# MAILBOX13 register map
Vendor: Texas Instruments
Peripheral module from a debugger description file (folder am571x).
Registers are 32-bit, read-only, reset 0x0 unless marked. A register's access mark holds for its fields unless they carry their own. Offsets are as the file gives them; lines under a group give offsets from that group; [hi:lo] are bit positions; {n}, {i} and the like mark numbered series; 'fields as' and 'values as' point back to an identical list; <NAME> marks a mode.

## MAILBOX13
0x00 MAILBOX_REVISION reset not defined — This register contains the IP revision code
  [31:0] REVISION — IP Revision
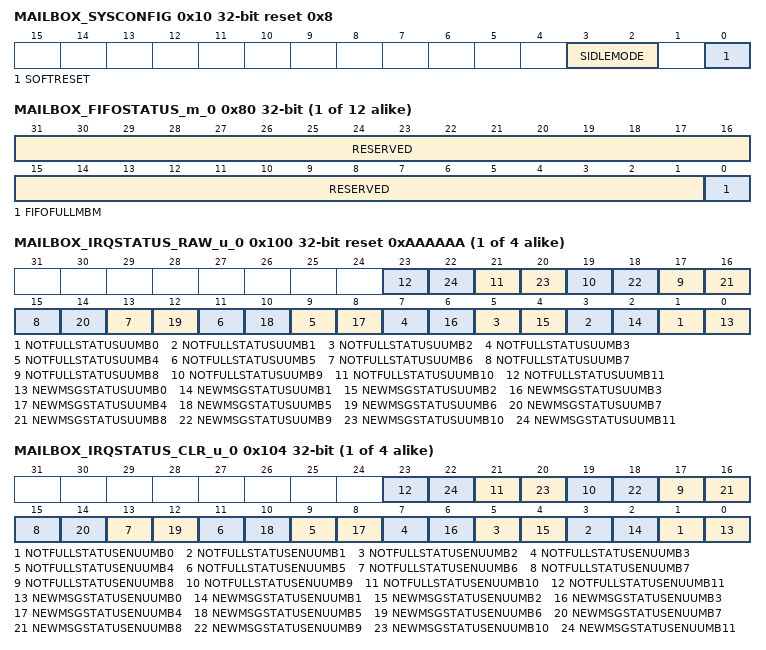
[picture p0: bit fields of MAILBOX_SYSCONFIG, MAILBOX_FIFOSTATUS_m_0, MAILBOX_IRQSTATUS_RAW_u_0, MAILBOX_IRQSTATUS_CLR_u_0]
0x10 MAILBOX_SYSCONFIG rw reset 0x8 — This register controls the various parameters of the communication interface
  [3:2] SIDLEMODE — Idle Mode
    0=b00 (Force-idle. An idle request is acknowledged unconditionally); 1=b01 (No-idle. An idle request is never acknowledged); 2=b10 (Smart-idle. Acknowledgement to an idle request is given based on the internal activity of the module based on the internal activity of the module); 3=b11 (reserved do not use)
  [0] SOFTRESET
    0=b0 (Soft/Hard reset done); 0=b0 (No action); 1=b1 (Reset is ongoing); 1=b1 (Start the soft reset sequence)
{0x40+4i} MAILBOX_MESSAGE_m_{i} rw (i=0..11) — The message register stores the next to be read message of the mailbox. Reads remove the message from the FIFO queue.
  [31:0] MESSAGEVALUEMBM — Message in Mailbox
{0x80+4i} MAILBOX_FIFOSTATUS_m_{i} (i=0..11) — The FIFO status register has the status related to the mailbox internal FIFO
  [31:1] RESERVED — Reads returns 0
  [0] FIFOFULLMBM — Full flag for Mailbox
    0=Mailbox_FIFO_is_not_full; 1=Mailbox_FIFO_is_full
{0xC0+4i} MAILBOX_MSGSTATUS_m_{i} (i=0..11) — The message status register has the status of the messages in the mailbox.
  [2:0] NBOFMSGMBM — Number of unread messages in Mailbox Note: Limited to four messages per mailbox.
{0x100+0x10*i} MAILBOX_IRQSTATUS_RAW_u_{i} access per field reset 0xAAAAAA (i=0..3) — The interrupt status register has the raw status for each event that may be responsible for the generation of an interrupt to the corresponding user - write 1 to a given bit sets this bit. This register is mainly used for debug purpose.
  [2n+1] NOTFULLSTATUSUUMB{n} rw (n=0..11) — NotFull Status bit for User u, Mailbox {n}
    0=No_event_pending_(message_queue_full); 0=No_action; 1=Event_pending_(message_queue_not_full); 1=Set_the_event_(for_debug)
  [2n] NEWMSGSTATUSUUMB{n} rw (n=0..11) — NewMessage Status bit for User u, Mailbox {n}
    0=No_event_(message)_pending; 0=No_action; 1=Event_(message)_pending; 1=Set_the_event_(for_debug)
{0x104+0x10*i} MAILBOX_IRQSTATUS_CLR_u_{i} access per field (i=0..3) — The interrupt status register has the status combined with irq-enable for each event that may be responsible for the generation of an interrupt to the corresponding user - write 1 to a given bit resets this bit
  [2n+1] NOTFULLSTATUSENUUMB{n} rw (n=0..11) — NotFull Status bit for User u, Mailbox {n}
    0=No_event_pending_(message_queue_full); 0=No_action; 1=Event_pending_(message_queue_not_full); 1=Clear_pending_event,_if_any
  [2n] NEWMSGSTATUSENUUMB{n} rw (n=0..11) — NewMessage Status bit for User u, Mailbox {n}
    0=No_event_(message)_pending; 0=No_action; 1=Event_(message)_pending; 1=Clear_pending_event,_if_any
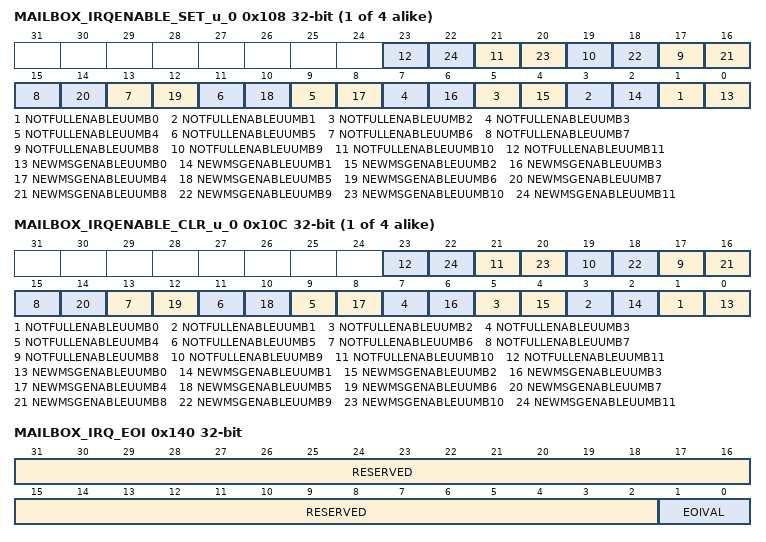
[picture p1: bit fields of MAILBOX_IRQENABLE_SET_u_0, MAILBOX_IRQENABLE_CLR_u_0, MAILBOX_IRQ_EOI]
{0x108+0x10*i} MAILBOX_IRQENABLE_SET_u_{i} access per field (i=0..3) — The interrupt enable register enables to unmask the module internal source of interrupt to the corresponding user. This register is write 1 to set.
  [all] fields
    0=Interupt_disabled; 0=No_action; 1=Interrupt_enabled; 1=Enable_interrupt
  [2n+1] NOTFULLENABLEUUMB{n} rw (n=0..11) — NotFull Enable bit for User u, Mailbox {n}
  [2n] NEWMSGENABLEUUMB{n} rw (n=0..11) — NewMessage Enable bit for User u, Mailbox {n}
{0x10C+0x10*i} MAILBOX_IRQENABLE_CLR_u_{i} access per field (i=0..3) — The interrupt enable register enables to mask the module internal source of interrupt to the corresponding user. This register is write 1 to clear.
  [all] fields
    0=Interupt_disabled; 0=No_action; 1=Interrupt_enabled; 1=Disable_interrupt
  [2n+1] NOTFULLENABLEUUMB{n} rw (n=0..11) — NotFull Enable bit for User u, Mailbox {n}
  [2n] NEWMSGENABLEUUMB{n} rw (n=0..11) — NewMessage Enable bit for User u, Mailbox {n}
0x140 MAILBOX_IRQ_EOI wo — This register is used for the software EOI clearance of the pulse. This register being write only gives 0 on read.
  [31:2] RESERVED — Write 0's for future compatibility. Reads returns 0
  [1:0] EOIVAL — EOI value
    0=B0 (EOI val first bit); 1=B1 (EOI val second bit)
